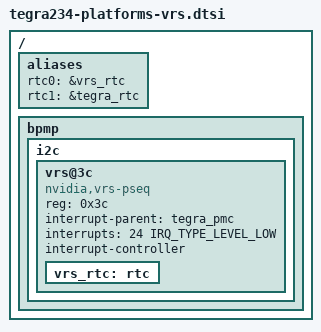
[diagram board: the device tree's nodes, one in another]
/*
 * Copyright (c) 2021, NVIDIA CORPORATION.  All rights reserved.
 *
 * This program is free software; you can redistribute it and/or modify
 * it under the terms of the GNU General Public License as published by
 * the Free Software Foundation; either version 2 of the License, or
 * (at your option) any later version.
 *
 * This program is distributed in the hope that it will be useful, but WITHOUT
 * ANY WARRANTY; without even the implied warranty of MERCHANTABILITY or
 * FITNESS FOR A PARTICULAR PURPOSE.  See the GNU General Public License for
 * more details.
 */

#include <dt-bindings/interrupt-controller/irq.h>

/ {
	aliases {
		rtc0 = &vrs_rtc;
		rtc1 = &tegra_rtc;
	};

	bpmp {
		i2c {
			vrs@3c {
				compatible = "nvidia,vrs-pseq";
				reg = <0x3c>;
				interrupt-parent = <&tegra_pmc>;
				/* VRS Wake ID is 24 */
				interrupts = <24 IRQ_TYPE_LEVEL_LOW>;
				interrupt-controller;
				#interrupt-cells = <2>;
				status = "okay";

				vrs_rtc: rtc {
					status = "okay";
				};
			};
		};
	};
};
